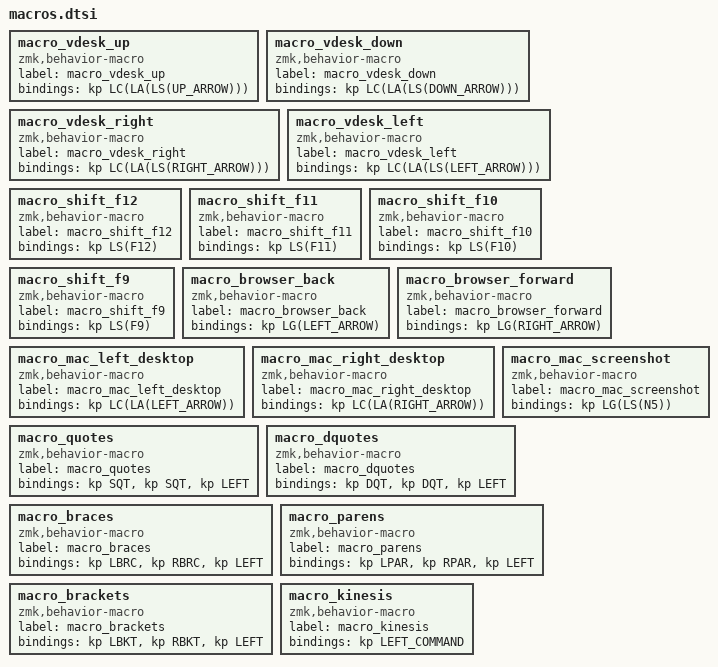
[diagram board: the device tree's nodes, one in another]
macro_vdesk_up: macro_vdesk_up{
compatible = "zmk,behavior-macro";
label = "macro_vdesk_up";
#binding-cells = <0>;
bindings = <&kp LC(LA(LS(UP_ARROW)))>;
};
macro_vdesk_down: macro_vdesk_down{
compatible = "zmk,behavior-macro";
label = "macro_vdesk_down";
#binding-cells = <0>;
bindings = <&kp LC(LA(LS(DOWN_ARROW)))>;
};
macro_vdesk_right: macro_vdesk_right{
compatible = "zmk,behavior-macro";
label = "macro_vdesk_right";
#binding-cells = <0>;
bindings = <&kp LC(LA(LS(RIGHT_ARROW)))>;
};
macro_vdesk_left: macro_vdesk_left{
compatible = "zmk,behavior-macro";
label = "macro_vdesk_left";
#binding-cells = <0>;
bindings = <&kp LC(LA(LS(LEFT_ARROW)))>;
};
macro_shift_f12: macro_shift_f12{
compatible = "zmk,behavior-macro";
label = "macro_shift_f12";
#binding-cells = <0>;
bindings = <&kp LS(F12)>;
};
macro_shift_f11: macro_shift_f11{
compatible = "zmk,behavior-macro";
label = "macro_shift_f11";
#binding-cells = <0>;
bindings = <&kp LS(F11)>;
};
macro_shift_f10: macro_shift_f10{
compatible = "zmk,behavior-macro";
label = "macro_shift_f10";
#binding-cells = <0>;
bindings = <&kp LS(F10)>;
};
macro_shift_f9: macro_shift_f9{
compatible = "zmk,behavior-macro";
label = "macro_shift_f9";
#binding-cells = <0>;
bindings = <&kp LS(F9)>;
};
macro_browser_back: macro_browser_back{
compatible = "zmk,behavior-macro";
label = "macro_browser_back";
#binding-cells = <0>;
bindings = <&kp LG(LEFT_ARROW)>;
};
macro_browser_forward: macro_browser_forward{
compatible = "zmk,behavior-macro";
label = "macro_browser_forward";
#binding-cells = <0>;
bindings = <&kp LG(RIGHT_ARROW)>;
};
macro_mac_left_desktop: macro_mac_left_desktop{
compatible = "zmk,behavior-macro";
label = "macro_mac_left_desktop";
#binding-cells = <0>;
bindings = <&kp LC(LA(LEFT_ARROW))>;
};
macro_mac_right_desktop: macro_mac_right_desktop{
compatible = "zmk,behavior-macro";
label = "macro_mac_right_desktop";
#binding-cells = <0>;
bindings = <&kp LC(LA(RIGHT_ARROW))>;
};
macro_mac_screenshot: macro_mac_screenshot{
compatible = "zmk,behavior-macro";
label = "macro_mac_screenshot";
#binding-cells = <0>;
bindings = <&kp LG(LS(N5))>;
};
macro_quotes: macro_quotes{
compatible = "zmk,behavior-macro";
label = "macro_quotes";
#binding-cells = <0>;
bindings = <&kp SQT>, <&kp SQT>, <&kp LEFT>;
};
macro_dquotes: macro_dquotes{
compatible = "zmk,behavior-macro";
label = "macro_dquotes";
#binding-cells = <0>;
bindings = <&kp DQT>, <&kp DQT>, <&kp LEFT>;
};
macro_braces: macro_braces{
compatible = "zmk,behavior-macro";
label = "macro_braces";
#binding-cells = <0>;
bindings = <&kp LBRC>, <&kp RBRC>, <&kp LEFT>;
};
macro_parens: macro_parens{
compatible = "zmk,behavior-macro";
label = "macro_parens";
#binding-cells = <0>;
bindings = <&kp LPAR>, <&kp RPAR>, <&kp LEFT>;
};
macro_brackets: macro_brackets{
compatible = "zmk,behavior-macro";
label = "macro_brackets";
#binding-cells = <0>;
bindings = <&kp LBKT>, <&kp RBKT>, <&kp LEFT>;
};
macro_kinesis: macro_kinesis{
compatible = "zmk,behavior-macro";
label = "macro_kinesis";
#binding-cells = <0>;
bindings = <&kp LEFT_COMMAND>;
};
